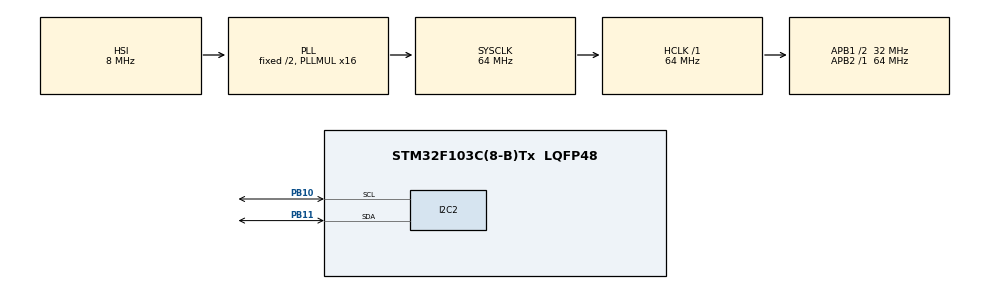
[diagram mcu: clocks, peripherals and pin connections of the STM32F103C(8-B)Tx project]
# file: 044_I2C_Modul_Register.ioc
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Mcu.Family=STM32F1
Mcu.Name=STM32F103C(8-B)Tx
Mcu.Package=LQFP48
NVIC.PriorityGroup=NVIC_PRIORITYGROUP_4
PA13.Mode=Serial_Wire
PA13.Signal=SYS_JTMS-SWDIO
PA14.Mode=Serial_Wire
PA14.Signal=SYS_JTCK-SWCLK
PB10.Mode=I2C
PB10.Signal=I2C2_SCL
PB11.Mode=I2C
PB11.Signal=I2C2_SDA
ProjectManager.HeapSize=0x200
ProjectManager.StackSize=0x400
ProjectManager.TargetToolchain=STM32CubeIDE
RCC.AHBFreq_Value=64000000
RCC.APB1CLKDivider=RCC_HCLK_DIV2
RCC.APB1Freq_Value=32000000
RCC.APB1TimFreq_Value=64000000
RCC.APB2Freq_Value=64000000
RCC.APB2TimFreq_Value=64000000
RCC.HCLKFreq_Value=64000000
RCC.PLLMUL=RCC_PLL_MUL16
RCC.SYSCLKFreq_VALUE=64000000
RCC.SYSCLKSource=RCC_SYSCLKSOURCE_PLLCLK
RCC.USBFreq_Value=64000000
board=custom

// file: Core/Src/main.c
/* USER CODE BEGIN Header */
/**
  ******************************************************************************
  * @file           : main.c
  * @brief          : Main program body
  ******************************************************************************
  * @attention                    <<<--------------------------------------------!! KARŞILAŞTIĞIM SORUNLAR ÖNEMLİ !! -----------------
  *
  *	1- PERİHPHERAL ENABLE BİTİ HER YAZMA İŞLEMİNDEN ÖNCE SET EDİLMELİ
  *	2- GPIO PİNLERİ MODLARINA DİKKAT ET SET ETTİĞİN BİTLER DIŞINDA RESET YAPMAN GEREKEBİLİR ( 10 YAZILMASI GEREKİYOR FAKAT GPIOA-> CRL |= (1 << 1) YETERLİ DEĞİL, &= ~(1<<0) LAZIM
  * 3- I2C2->DR REGISTERLARINA SET İŞLEMİNİ DİREKT = İLE YAP, |= İLE DEĞİL. ( I2C2->DR = 23 ✓ , I2C2->DR |= 23 ✕ )
  * Copyright (c) 2024 STMicroelectronics.
  * All rights reserved.
  *
  * This software is licensed under terms that can be found in the LICENSE file
  * in the root directory of this software component.
  * If no LICENSE file comes with this software, it is provided AS-IS.
  *
  ******************************************************************************
  */
/* USER CODE END Header */
#include "main.h"

/* USER CODE BEGIN PD */
#define m_address 0x4E

/* USER CODE END PD */

I2C_HandleTypeDef hi2c2;

/* USER CODE BEGIN PV */
uint8_t i;
uint16_t j = 0;

/* USER CODE END PV */

void SystemClock_Config(void);
static void MX_GPIO_Init(void);
static void MX_I2C2_Init(void);
/* USER CODE BEGIN PFP */
void RCC_Config(void);
void Gpio_Config(void);
void I2C_Config(void);
void I2C_Write(uint8_t address, uint8_t data);
//void I2C_Read(uint8_t address, uint8_t data);
void delay(uint32_t time);
void Scan_Slave_Address(void);

/* USER CODE END PFP */

int main(void)
{

  /* MCU Configuration--------------------------------------------------------*/

  /* Reset of all peripherals, Initializes the Flash interface and the Systick. */
  HAL_Init();

  /* Configure the system clock */
  SystemClock_Config();

  /* Initialize all configured peripherals */
  MX_GPIO_Init();
  MX_I2C2_Init();
  /* USER CODE BEGIN 2 */

  RCC_Config();
  Gpio_Config();
  I2C_Config();
  Scan_Slave_Address();
  /* USER CODE END 2 */

  /* Infinite loop */
  while (1)
  {

    /* USER CODE BEGIN 3 */
	  if(GPIOA->IDR & (0x1) ){
		  while(GPIOA->IDR & GPIO_PIN_SET);
		  i++;
		  delay(2100000);
	  }

	  switch (i){

	  case 0:
		  I2C_Write(m_address,0X00);
		  break;
	  case 1:
		  I2C_Write(m_address,0X01);
		  break;
	  case 2:
		  I2C_Write(m_address,0X02);
		  break;
	  case 3:
		  I2C_Write(m_address,0x04);
		  break;
	  case 4:
		  I2C_Write(m_address,0x08);
		  break;
	  case 5:
		  I2C_Write(m_address,0x10);
		  break;
	  case 6:
		  I2C_Write(m_address,0x20);
		  break;
	  case 7:
		  I2C_Write(m_address,0x40);
		  break;
	  case 8:
		  I2C_Write(m_address,0x80);
		  break;

	  default:
		  i = 0;
		  break;
	  }
  }
  /* USER CODE END 3 */
}

void SystemClock_Config(void)
{
  RCC_OscInitTypeDef RCC_OscInitStruct = {0};
  RCC_ClkInitTypeDef RCC_ClkInitStruct = {0};

  /** Initializes the RCC Oscillators according to the specified parameters
  * in the RCC_OscInitTypeDef structure.
  */
  RCC_OscInitStruct.OscillatorType = RCC_OSCILLATORTYPE_HSI;
  RCC_OscInitStruct.HSIState = RCC_HSI_ON;
  RCC_OscInitStruct.HSICalibrationValue = RCC_HSICALIBRATION_DEFAULT;
  RCC_OscInitStruct.PLL.PLLState = RCC_PLL_ON;
  RCC_OscInitStruct.PLL.PLLSource = RCC_PLLSOURCE_HSI_DIV2;
  RCC_OscInitStruct.PLL.PLLMUL = RCC_PLL_MUL16;
  if (HAL_RCC_OscConfig(&RCC_OscInitStruct) != HAL_OK)
  {
    Error_Handler();
  }

  /** Initializes the CPU, AHB and APB buses clocks
  */
  RCC_ClkInitStruct.ClockType = RCC_CLOCKTYPE_HCLK|RCC_CLOCKTYPE_SYSCLK
                              |RCC_CLOCKTYPE_PCLK1|RCC_CLOCKTYPE_PCLK2;
  RCC_ClkInitStruct.SYSCLKSource = RCC_SYSCLKSOURCE_PLLCLK;
  RCC_ClkInitStruct.AHBCLKDivider = RCC_SYSCLK_DIV1;
  RCC_ClkInitStruct.APB1CLKDivider = RCC_HCLK_DIV2;
  RCC_ClkInitStruct.APB2CLKDivider = RCC_HCLK_DIV1;

  if (HAL_RCC_ClockConfig(&RCC_ClkInitStruct, FLASH_LATENCY_2) != HAL_OK)
  {
    Error_Handler();
  }
}

static void MX_I2C2_Init(void)
{

  hi2c2.Instance = I2C2;
  hi2c2.Init.ClockSpeed = 100000;
  hi2c2.Init.DutyCycle = I2C_DUTYCYCLE_2;
  hi2c2.Init.OwnAddress1 = 0;
  hi2c2.Init.AddressingMode = I2C_ADDRESSINGMODE_7BIT;
  hi2c2.Init.DualAddressMode = I2C_DUALADDRESS_DISABLE;
  hi2c2.Init.OwnAddress2 = 0;
  hi2c2.Init.GeneralCallMode = I2C_GENERALCALL_DISABLE;
  hi2c2.Init.NoStretchMode = I2C_NOSTRETCH_DISABLE;
  if (HAL_I2C_Init(&hi2c2) != HAL_OK)
  {
    Error_Handler();
  }

}

static void MX_GPIO_Init(void)
{

  /* GPIO Ports Clock Enable */
  __HAL_RCC_GPIOB_CLK_ENABLE();
  __HAL_RCC_GPIOA_CLK_ENABLE();

}

/* USER CODE BEGIN 4 */

void Scan_Slave_Address(void){

	for(j=0; j <= 255 ; j++){
		if(HAL_I2C_IsDeviceReady(&hi2c2, j, 1, 100) == HAL_OK)
			break;
	}
}

void delay(uint32_t time){
	while(time--);
}

void RCC_Config(void){

	RCC->CR |= 0x03;                                    // hsi and hsiready on
	while(!(RCC->CR & (1<<1)));                         //wait hsi ready
	RCC->CR |= (1 << 19);								// CSS ON
	RCC->CFGR &= ~(1 << 16);                            // HSI SOURCE HSI
	RCC->CFGR = 0x0140000;								// pll x7
	RCC->CFGR |= (1<<1);								//PLL AS SYSTEM CLOCK
	RCC->CFGR |= (1 << 14);                             // ADC PRESCALER /4
	RCC->CIR  &= ~(0x0840000);							//flag reset(css and hsi)

}

void Gpio_Config(void){

	RCC->APB2ENR |= (0x0D << 0);  						// AF GPIOA GPIOB CLK ENABLE

	GPIOA->CRL |= (1<<3);								// A0 input
	GPIOA->CRL &= ~(1<<2);

	GPIOB->CRH |= (0xDD00); 							// B10 & B11 AF_OD - 10MHZ

}

void I2C_Config(void){

	RCC->APB1ENR |= (1 << 22); 							// I2C2 ENABLE

	I2C2->CR2 |= 0;
	I2C2->TRISE |= 0x009;
	I2C2->CR2 |= 0b01000;								// FREQ= 8 MHZ
	I2C2->CCR |= (0x8028);								// 100 khz scl freq
	I2C2->CR1 |= (1 << 0);								// peripheral enable

}

void I2C_Write(uint8_t address, uint8_t wRegister){
	I2C2->CR1 |= (1 << 0);								// PE ENABLE
	I2C2->CR1 |= (1 << 8);								// send START bit
	while(!(I2C2->SR1 & 0x0001));						// wait for start
	I2C2->DR = address;									// SLAVE ADDRESS
	while(!(I2C2->SR1 & 0x002));						// wait till address send
	while(!(I2C2->SR2 & 0x001));						// wait msl ( master or slave) cihaz master moda girdi mi
	while(!(I2C2->SR1 & 1 << 7));						// wait txe empty
	I2C2->DR = wRegister;
	while(!(I2C2->SR1 & 1 << 7));						// wait txe empty
	while(!(I2C2->SR1 & 0x04));							// wait btf empty byte transfer finished
	I2C2->CR1 = (1<<9);									// SEND STOP BIT
}

//void I2C_Read(void){
//
//
//
//}

/* USER CODE END 4 */

void Error_Handler(void)
{
  __disable_irq();
  while (1)
  {
  }
}
